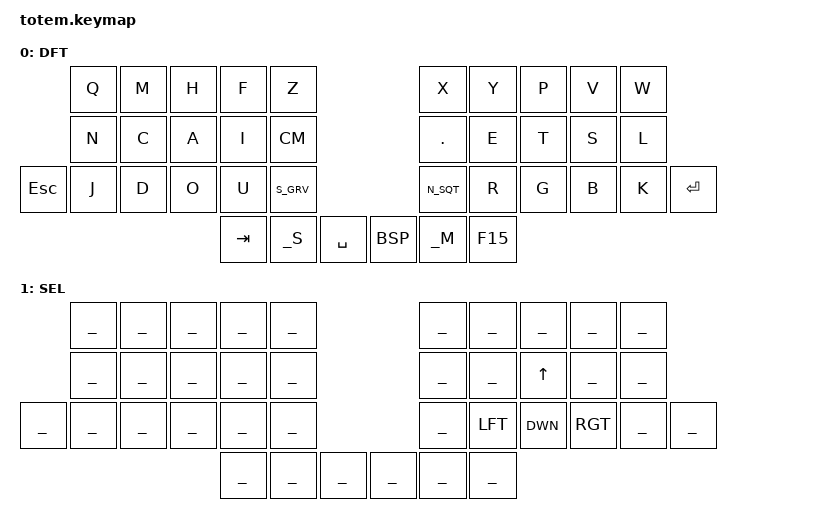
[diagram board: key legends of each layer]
//
//                                                        ▀▀▀▀▀     ▀▀▀▀▀          ▀▀█▀▀
//                                                        ▄▀▀▀▄  ▄  ▄▀▀▀▄  ▄  ▄▀▀▀▄  █  ▄▀▀▀▄
//                                                        █   █  █  █   █  █  █   █  █  █   █
//                                                         ▀▀▀   █   ▀▀▀   █   ▀▀▀   ▀   ▀▀▀
//                                                               █      ▄▄▄█▄▄▄    █   █
//                                                               ▀      █  █  █     █▄█
//                                                             ▀▀▀▀▀    █  █  █      ▀
//                                                                      ▀  ▀  ▀
//
// ▄▄▄▄▄▄▄▄▄▄▄▄▄▄▄▄▄▄▄▄▄▄▄▄▄▄▄▄▄▄▄▄▄▄▄▄▄▄▄▄▄▄▄▄▄▄▄▄▄▄▄▄▄▄▄▄▄▄▄▄▄▄▄▄▄▄▄▄▄▄▄▄▄▄▄▄▄▄▄▄▄▄▄▄▄▄▄▄▄▄▄▄▄▄▄▄▄▄▄▄▄▄▄▄▄▄▄▄▄▄▄▄▄▄▄▄▄▄▄▄▄▄▄▄▄▄▄▄▄▄▄▄▄▄▄▄▄▄▄▄▄▄▄▄▄▄▄▄▄

#include <behaviors.dtsi>
#include <dt-bindings/zmk/bt.h>
#include <dt-bindings/zmk/keys.h>
#include <dt-bindings/zmk/outputs.h>

#include "includes/aliases.dtsi"
#include "includes/behaviors.dtsi"
#include "includes/combos.dtsi"

#define DFT 0
#define SEL 1

&mt {
    quick-tap-ms = <100>;
    global-quick-tap;
    flavor = "tap-preferred";
    tapping-term-ms = <170>;
};

/ {

    keymap {
        compatible = "zmk,keymap";
// ▄▄▄▄▄▄▄▄▄▄▄▄▄▄▄▄▄▄▄▄▄▄▄▄▄▄▄▄▄▄▄▄▄▄▄▄▄▄▄▄▄▄▄▄▄▄▄▄▄▄▄▄▄▄▄▄▄▄▄▄▄▄▄▄▄▄▄▄▄▄▄▄▄▄▄▄▄▄▄▄▄▄▄▄▄▄▄▄▄▄▄▄▄▄▄▄▄▄▄▄▄▄▄▄▄▄▄▄▄▄▄▄▄▄▄▄▄▄▄▄▄▄▄▄▄▄▄▄▄▄▄▄▄▄▄▄▄▄▄▄▄▄▄▄▄▄▄▄▄
        Default {
//    ┏━━━━━━━━━━━━━━━━━━━━━━━━━━━━━━━━━━━━━━┓
    display-name= "DFT"                       ;
//    ┗━━━━━━━━━━━━━━━━━━━━━━━━━━━━━━━━━━━━━━┛

    bindings = <
//  ╷           ╷           ╷           ╷           ╷           ╷           ╷           ╷   ╷           ╷           ╷           ╷           ╷           ╷           ╷           ╷
//              ┏━━━━━━━━━━━┳━━━━━━━━━━━┳━━━━━━━━━━━┳━━━━━━━━━━━┳━━━━━━━━━━━┓                           ┏━━━━━━━━━━━┳━━━━━━━━━━━┳━━━━━━━━━━━┳━━━━━━━━━━━┳━━━━━━━━━━━┓
                    &kp Q       &kp M       &kp H       &kp F       &kp Z                                   &kp X       &kp Y       &kp P       &kp V       &kp W
//              ┣━━━━━━━━━━━╋━━━━━━━━━━━╋━━━━━━━━━━━╋━━━━━━━━━━━╋━━━━━━━━━━━┫                           ┣━━━━━━━━━━━╋━━━━━━━━━━━╋━━━━━━━━━━━╋━━━━━━━━━━━╋━━━━━━━━━━━┫
                    &kp N       &kp C       &kp A       &kp I       &kp CM                                  &kp DOT     &kp E       &kp T       &kp S       &kp L
//  ┏━━━━━━━━━━━╋━━━━━━━━━━━╋━━━━━━━━━━━╋━━━━━━━━━━━╋━━━━━━━━━━━╋━━━━━━━━━━━┫                           ┣━━━━━━━━━━━╋━━━━━━━━━━━╋━━━━━━━━━━━╋━━━━━━━━━━━╋━━━━━━━━━━━╋━━━━━━━━━━━┓
       &kp ESC      &kp J       &kp D       &kp O       &kp U       S_GRV                                   N_SQT     &kp R       &kp G       &kp B       &kp K       &kp RET
//  ┗━━━━━━━━━━━┻━━━━━━━━━━━┻━━━━━━━━━━━┗━━━━━━━━━━━╋━━━━━━━━━━━╋━━━━━━━━━━━┫━━━━━━━━━━━┓   ┏━━━━━━━━━━━┣━━━━━━━━━━━╋━━━━━━━━━━━╋━━━━━━━━━━━┛━━━━━━━━━━━┻━━━━━━━━━━━┻━━━━━━━━━━━┛
                                                        &kp TAB     &kp _S      &kp SPC         &kp BSP     &kp _M      &kp F15
//                                                  ┗━━━━━━━━━━━┻━━━━━━━━━━━┻━━━━━━━━━━━┛   ┗━━━━━━━━━━━┻━━━━━━━━━━━┻━━━━━━━━━━━┛
            >;
    }; // end Default

// ▄▄▄▄▄▄▄▄▄▄▄▄▄▄▄▄▄▄▄▄▄▄▄▄▄▄▄▄▄▄▄▄▄▄▄▄▄▄▄▄▄▄▄▄▄▄▄▄▄▄▄▄▄▄▄▄▄▄▄▄▄▄▄▄▄▄▄▄▄▄▄▄▄▄▄▄▄▄▄▄▄▄▄▄▄▄▄▄▄▄▄▄▄▄▄▄▄▄▄▄▄▄▄▄▄▄▄▄▄▄▄▄▄▄▄▄▄▄▄▄▄▄▄▄▄▄▄▄▄▄▄▄▄▄▄▄▄▄▄▄▄▄▄▄▄▄▄▄▄
    select {
//    ┏━━━━━━━━━━━━━━━━━━━━━━━━━━━━━━━━━━━━━━┓
    display-name= "SEL"                       ;
//    ┗━━━━━━━━━━━━━━━━━━━━━━━━━━━━━━━━━━━━━━┛

    bindings = <
        // ╷                ╷                ╷                ╷                ╷                ╷                ╷                ╷    ╷                ╷                ╷                ╷                ╷                ╷                ╷                ╷
        //                ┏━━━━━━━━━━━┳━━━━━━━━━━━┳━━━━━━━━━━━┳━━━━━━━━━━━┳━━━━━━━━━━━┓                            ┏━━━━━━━━━━━┳━━━━━━━━━━━┳━━━━━━━━━━━┳━━━━━━━━━━━┳━━━━━━━━━━━┓
                              ___            ___        ___         ___         ___                                    ___            ___        ___         ___         ___
        //                ┣━━━━━━━━━━━╋━━━━━━━━━━━╋━━━━━━━━━━━╋━━━━━━━━━━━╋━━━━━━━━━━━┫                            ┣━━━━━━━━━━━╋━━━━━━━━━━━╋━━━━━━━━━━━╋━━━━━━━━━━━╋━━━━━━━━━━━┫
                              ___         ___        ___         ___         ___                                     ___            ___    &kp UP        ___            ___
        //    ┏━━━━━━━━━━━╋━━━━━━━━━━━╋━━━━━━━━━━━╋━━━━━━━━━━━╋━━━━━━━━━━━╋━━━━━━━━━━━┫                            ┣━━━━━━━━━━━╋━━━━━━━━━━━╋━━━━━━━━━━━╋━━━━━━━━━━━╋━━━━━━━━━━━╋━━━━━━━━━━━┓
                ___            ___         ___        ___         ___           ___                                     ___       &kp LFT      &kp DWN   &kp RGT        ___            ___
        //    ┗━━━━━━━━━━━┻━━━━━━━━━━━┻━━━━━━━━━━━┗━━━━━━━━━━━╋━━━━━━━━━━━╋━━━━━━━━━━━┫━━━━━━━━━━━┓   ┏━━━━━━━━━━━┣━━━━━━━━━━━╋━━━━━━━━━━━╋━━━━━━━━━━━┛━━━━━━━━━━━┻━━━━━━━━━━━┻━━━━━━━━━━━┛
                                                                ___            ___         ___            ___            ___            ___
        //                                                    ┗━━━━━━━━━━━┻━━━━━━━━━━━┻━━━━━━━━━━━┛    ┗━━━━━━━━━━━┻━━━━━━━━━━━┻━━━━━━━━━━━┛
            >;
        };  // end Select
    };
};
